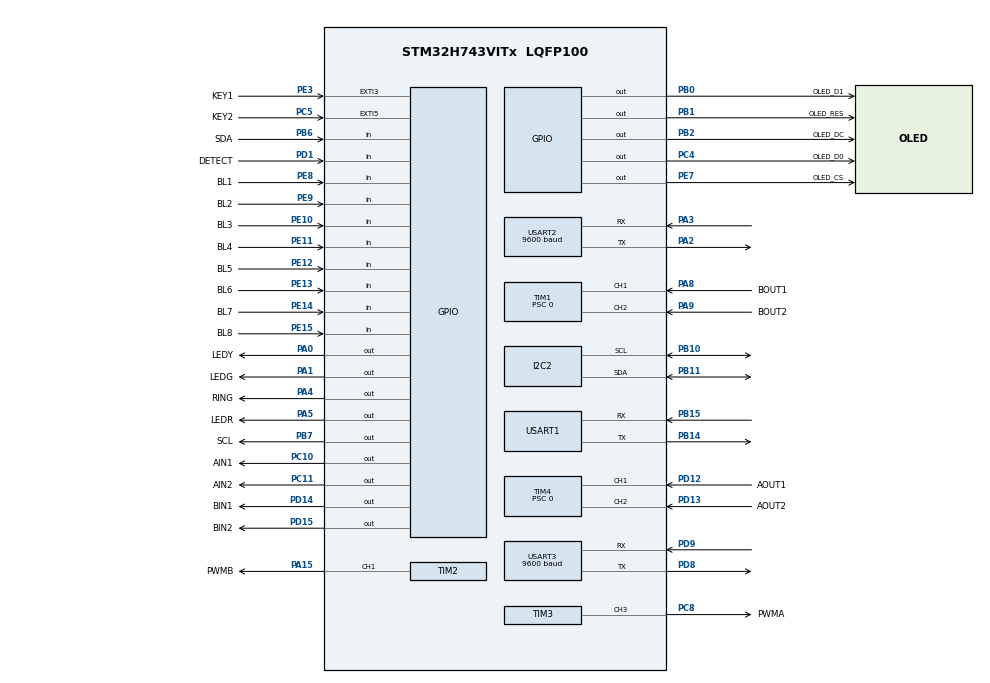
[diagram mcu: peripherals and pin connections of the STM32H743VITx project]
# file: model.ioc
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CORTEX_M7.AccessPermission-Cortex_Memory_Protection_Unit_Region0_Settings=MPU_REGION_FULL_ACCESS
CORTEX_M7.AccessPermission-Cortex_Memory_Protection_Unit_Region1_Settings=MPU_REGION_FULL_ACCESS
CORTEX_M7.AccessPermission-Cortex_Memory_Protection_Unit_Region2_Settings=MPU_REGION_FULL_ACCESS
CORTEX_M7.AccessPermission-Cortex_Memory_Protection_Unit_Region3_Settings=MPU_REGION_FULL_ACCESS
CORTEX_M7.AccessPermission-Cortex_Memory_Protection_Unit_Region4_Settings=MPU_REGION_FULL_ACCESS
CORTEX_M7.BaseAddress-Cortex_Memory_Protection_Unit_Region0_Settings=0x24000000
CORTEX_M7.BaseAddress-Cortex_Memory_Protection_Unit_Region1_Settings=0x30000000
CORTEX_M7.BaseAddress-Cortex_Memory_Protection_Unit_Region2_Settings=0x30020000
CORTEX_M7.BaseAddress-Cortex_Memory_Protection_Unit_Region3_Settings=0x30040000
CORTEX_M7.BaseAddress-Cortex_Memory_Protection_Unit_Region4_Settings=0x38000000
CORTEX_M7.CPU_DCache=Enabled
CORTEX_M7.CPU_ICache=Enabled
CORTEX_M7.Enable-Cortex_Memory_Protection_Unit_Region0_Settings=MPU_REGION_ENABLE
CORTEX_M7.Enable-Cortex_Memory_Protection_Unit_Region1_Settings=MPU_REGION_ENABLE
CORTEX_M7.Enable-Cortex_Memory_Protection_Unit_Region2_Settings=MPU_REGION_ENABLE
CORTEX_M7.Enable-Cortex_Memory_Protection_Unit_Region3_Settings=MPU_REGION_ENABLE
CORTEX_M7.Enable-Cortex_Memory_Protection_Unit_Region4_Settings=MPU_REGION_ENABLE
CORTEX_M7.IsBufferable-Cortex_Memory_Protection_Unit_Region0_Settings=MPU_ACCESS_BUFFERABLE
CORTEX_M7.IsCacheable-Cortex_Memory_Protection_Unit_Region0_Settings=MPU_ACCESS_CACHEABLE
CORTEX_M7.MPU_Control=MPU_PRIVILEGED_DEFAULT
CORTEX_M7.Size-Cortex_Memory_Protection_Unit_Region0_Settings=MPU_REGION_SIZE_512KB
CORTEX_M7.Size-Cortex_Memory_Protection_Unit_Region1_Settings=MPU_REGION_SIZE_128KB
CORTEX_M7.Size-Cortex_Memory_Protection_Unit_Region2_Settings=MPU_REGION_SIZE_128KB
CORTEX_M7.Size-Cortex_Memory_Protection_Unit_Region3_Settings=MPU_REGION_SIZE_32KB
CORTEX_M7.Size-Cortex_Memory_Protection_Unit_Region4_Settings=MPU_REGION_SIZE_64KB
CORTEX_M7.TypeExtField-Cortex_Memory_Protection_Unit_Region0_Settings=MPU_TEX_LEVEL1
CORTEX_M7.TypeExtField-Cortex_Memory_Protection_Unit_Region1_Settings=MPU_TEX_LEVEL1
CORTEX_M7.TypeExtField-Cortex_Memory_Protection_Unit_Region2_Settings=MPU_TEX_LEVEL1
CORTEX_M7.TypeExtField-Cortex_Memory_Protection_Unit_Region3_Settings=MPU_TEX_LEVEL1
CORTEX_M7.TypeExtField-Cortex_Memory_Protection_Unit_Region4_Settings=MPU_TEX_LEVEL1
I2C2.Timing=0x307075B1
Mcu.Family=STM32H7
Mcu.Name=STM32H743VITx
Mcu.Package=LQFP100
NVIC.EXTI3_IRQn=true\:14\:0\:true\:false\:true\:true\:true\:true
NVIC.EXTI9_5_IRQn=true\:15\:0\:true\:false\:true\:true\:true\:true
NVIC.PriorityGroup=NVIC_PRIORITYGROUP_4
NVIC.TIM4_IRQn=true\:3\:0\:true\:false\:true\:true\:true\:true
NVIC.TIM6_DAC_IRQn=true\:1\:0\:true\:false\:true\:true\:true\:true
NVIC.TIM7_IRQn=true\:5\:0\:true\:false\:true\:true\:true\:true
NVIC.USART2_IRQn=true\:0\:0\:false\:false\:true\:true\:true\:true
PA0.GPIO_Label=LEDY
PA0.Signal=GPIO_Output
PA1.GPIO_Label=LEDG
PA1.Signal=GPIO_Output
PA13\ (JTMS/SWDIO).Mode=Serial_Wire
PA13\ (JTMS/SWDIO).Signal=DEBUG_JTMS-SWDIO
PA14\ (JTCK/SWCLK).Mode=Serial_Wire
PA14\ (JTCK/SWCLK).Signal=DEBUG_JTCK-SWCLK
PA15\ (JTDI).GPIO_Label=PWMB 
PA15\ (JTDI).Signal=S_TIM2_CH1_ETR
PA2.Mode=Asynchronous
PA2.Signal=USART2_TX
PA3.Mode=Asynchronous
PA3.Signal=USART2_RX
PA4.GPIO_Label=RING
PA4.Signal=GPIO_Output
PA5.GPIO_Label=LEDR
PA5.Signal=GPIO_Output
PA8.GPIO_Label=BOUT1
PA8.Signal=S_TIM1_CH1
PA9.GPIO_Label=BOUT2
PA9.Signal=S_TIM1_CH2
PB0.GPIO_Label=OLED_D1
PB0.GPIO_PuPd=GPIO_PULLUP
PB0.Signal=GPIO_Output
PB1.GPIO_Label=OLED_RES
PB1.GPIO_PuPd=GPIO_PULLUP
PB1.Signal=GPIO_Output
PB10.Mode=I2C
PB10.Signal=I2C2_SCL
PB11.Mode=I2C
PB11.Signal=I2C2_SDA
PB14.Mode=Asynchronous
PB14.Signal=USART1_TX
PB15.Mode=Asynchronous
PB15.Signal=USART1_RX
PB2.GPIO_Label=OLED_DC
PB2.GPIO_PuPd=GPIO_PULLUP
PB2.Signal=GPIO_Output
PB6.GPIO_Label=SDA
PB6.GPIO_PuPd=GPIO_PULLUP
PB6.Signal=GPIO_Input
PB7.GPIO_Label=SCL
PB7.GPIO_ModeDefaultOutputPP=GPIO_MODE_OUTPUT_PP
PB7.GPIO_PuPd=GPIO_NOPULL
PB7.GPIO_Speed=GPIO_SPEED_FREQ_HIGH
PB7.PinState=GPIO_PIN_RESET
PB7.Signal=GPIO_Output
PC10.GPIO_Label=AIN1
PC10.Signal=GPIO_Output
PC11.GPIO_Label=AIN2
PC11.Signal=GPIO_Output
PC4.GPIO_Label=OLED_D0
PC4.GPIO_PuPd=GPIO_PULLUP
PC4.Signal=GPIO_Output
PC5.GPIO_Label=KEY2
PC5.GPIO_PuPd=GPIO_PULLUP
PC5.Signal=GPXTI5
PC8.GPIO_Label=PWMA
PC8.Signal=S_TIM3_CH3
PD1.GPIO_Label=DETECT
PD1.GPIO_PuPd=GPIO_PULLDOWN
PD1.Signal=GPIO_Input
PD12.GPIO_Label=AOUT1
PD12.Signal=S_TIM4_CH1
PD13.GPIO_Label=AOUT2
PD13.Signal=S_TIM4_CH2
PD14.GPIO_Label=BIN1
PD14.Signal=GPIO_Output
PD15.GPIO_Label=BIN2
PD15.Signal=GPIO_Output
PD8.Mode=Asynchronous
PD8.Signal=USART3_TX
PD9.Mode=Asynchronous
PD9.Signal=USART3_RX
PE10.GPIO_Label=BL3
PE10.GPIO_PuPd=GPIO_PULLUP
PE10.Signal=GPIO_Input
PE11.GPIO_Label=BL4
PE11.GPIO_PuPd=GPIO_PULLUP
PE11.Signal=GPIO_Input
PE12.GPIO_Label=BL5
PE12.GPIO_PuPd=GPIO_PULLUP
PE12.Signal=GPIO_Input
PE13.GPIO_Label=BL6
PE13.GPIO_PuPd=GPIO_PULLUP
PE13.Signal=GPIO_Input
PE14.GPIO_Label=BL7
PE14.GPIO_PuPd=GPIO_PULLUP
PE14.Signal=GPIO_Input
PE15.GPIO_Label=BL8
PE15.GPIO_PuPd=GPIO_PULLUP
PE15.Signal=GPIO_Input
PE3.GPIO_Label=KEY1
PE3.GPIO_PuPd=GPIO_PULLUP
PE3.Signal=GPXTI3
PE7.GPIO_Label=OLED_CS
PE7.GPIO_PuPd=GPIO_PULLUP
PE7.Signal=GPIO_Output
PE8.GPIO_Label=BL1
PE8.GPIO_PuPd=GPIO_PULLUP
PE8.Signal=GPIO_Input
PE9.GPIO_Label=BL2
PE9.GPIO_PuPd=GPIO_PULLUP
PE9.Signal=GPIO_Input
PH0-OSC_IN\ (PH0).Mode=HSE-External-Oscillator
PH0-OSC_IN\ (PH0).Signal=RCC_OSC_IN
PH1-OSC_OUT\ (PH1).Mode=HSE-External-Oscillator
PH1-OSC_OUT\ (PH1).Signal=RCC_OSC_OUT
ProjectManager.HeapSize=0x200
ProjectManager.StackSize=0x7400
ProjectManager.TargetToolchain=MDK-ARM V5.32
RCC.ADCFreq_Value=50390625
RCC.APB1Freq_Value=120000000
RCC.APB2Freq_Value=120000000
RCC.APB3Freq_Value=120000000
RCC.APB4Freq_Value=120000000
RCC.CortexFreq_Value=480000000
RCC.D1PPRE=RCC_APB3_DIV2
RCC.D2PPRE1=RCC_APB1_DIV2
RCC.D2PPRE2=RCC_APB2_DIV2
RCC.D3PPRE=RCC_APB4_DIV2
RCC.DIVM1=5
RCC.DIVN1=192
RCC.HCLKFreq_Value=240000000
RCC.HPRE=RCC_HCLK_DIV2
RCC.HSE_VALUE=25000000
RCC.PLLSourceVirtual=RCC_PLLSOURCE_HSE
RCC.PWR_Regulator_Voltage_Scale=PWR_REGULATOR_VOLTAGE_SCALE0
RCC.ProductRev=revV
RCC.SYSCLKFreq_VALUE=480000000
RCC.SYSCLKSource=RCC_SYSCLKSOURCE_PLLCLK
RCC.USBFreq_Value=480000000
SH.S_TIM1_CH1.0=TIM1_CH1,Encoder_Interface
SH.S_TIM1_CH2.0=TIM1_CH2,Encoder_Interface
SH.S_TIM2_CH1_ETR.0=TIM2_CH1,PWM Generation1 CH1
SH.S_TIM3_CH3.0=TIM3_CH3,PWM Generation3 CH3
SH.S_TIM4_CH1.0=TIM4_CH1,Encoder_Interface
SH.S_TIM4_CH2.0=TIM4_CH2,Encoder_Interface
TIM1.ClockDivision=TIM_CLOCKDIVISION_DIV1
TIM1.EncoderMode=TIM_ENCODERMODE_TI12
TIM1.IC1Filter=12
TIM1.IC1Prescaler=TIM_ICPSC_DIV1
TIM1.IC2Filter=12
TIM1.IC2Prescaler=TIM_ICPSC_DIV1
TIM1.Period=8000
TIM1.Prescaler=0
TIM13.Prescaler=239
TIM2.Channel-PWM\ Generation1\ CH1=TIM_CHANNEL_1
TIM3.Channel-PWM\ Generation3\ CH3=TIM_CHANNEL_3
TIM4.ClockDivision=TIM_CLOCKDIVISION_DIV1
TIM4.EncoderMode=TIM_ENCODERMODE_TI12
TIM4.IC1Filter=12
TIM4.IC1Prescaler=TIM_ICPSC_DIV1
TIM4.IC2Filter=12
TIM4.IC2Prescaler=TIM_ICPSC_DIV1
TIM4.Period=8000
TIM4.Prescaler=0
TIM6.Period=9999
TIM6.Prescaler=239
TIM7.Period=9999
TIM7.Prescaler=239
USART1.VirtualMode-Asynchronous=VM_ASYNC
USART2.BaudRate=9600
USART2.VirtualMode-Asynchronous=VM_ASYNC
USART3.BaudRate=9600
USART3.VirtualMode-Asynchronous=VM_ASYNC
VP_TIM13_VS_ClockSourceINT.Mode=Enable_Timer
VP_TIM17_VS_ClockSourceINT.Mode=Enable_Timer
VP_TIM2_VS_ClockSourceINT.Mode=Internal
VP_TIM3_VS_ClockSourceINT.Mode=Internal
VP_TIM6_VS_ClockSourceINT.Mode=Enable_Timer
VP_TIM7_VS_ClockSourceINT.Mode=Enable_Timer
board=custom

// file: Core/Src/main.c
/* USER CODE BEGIN Header */
/**
  ******************************************************************************
  * @file           : main.c
  * @brief          : Main program body
  ******************************************************************************
  * @attention
  *
  * Copyright (c) 2023 STMicroelectronics.
  * All rights reserved.
  *
  * This software is licensed under terms that can be found in the LICENSE file
  * in the root directory of this software component.
  * If no LICENSE file comes with this software, it is provided AS-IS.
  *
  ******************************************************************************
  */
/* USER CODE END Header */
#include "main.h"

/* USER CODE BEGIN PV */
//volatile bool key1state;
//volatile bool key2state;
volatile int led_beep_flag = 0;
uint8_t g_usart2_receivedata;
/* USER CODE END PV */

void SystemClock_Config(void);
static void MPU_Initialize(void);
static void MPU_Config(void);

int main(void)
{

  /* Enable I-Cache---------------------------------------------------------*/
  SCB_EnableICache();

  /* Enable D-Cache---------------------------------------------------------*/
  SCB_EnableDCache();

  /* MCU Configuration--------------------------------------------------------*/

  /* Reset of all peripherals, Initializes the Flash interface and the Systick. */
  HAL_Init();

  /* MPU Configuration--------------------------------------------------------*/
  MPU_Config();

  /* Configure the system clock */
  SystemClock_Config();

  /* Initialize all configured peripherals */
  MX_GPIO_Init();
  MX_TIM7_Init();
  MX_USART1_UART_Init();
  MX_I2C2_Init();
  MX_TIM1_Init();
  MX_TIM2_Init();
  MX_TIM3_Init();
  MX_TIM4_Init();
  MX_USART2_UART_Init();
  MX_TIM6_Init();
  MX_TIM13_Init();
  MX_TIM17_Init();
  MX_USART3_UART_Init();
  /* USER CODE BEGIN 2 */
  HAL_TIM_Base_Start_IT(&htim7);
  HAL_TIM_Base_Start_IT(&htim6);
	//MPU6050_Init();
	OLED_Init();
	TB6612_Init();
  /* USER CODE END 2 */

  /* Infinite loop */
  /* USER CODE BEGIN WHILE */
  while (1)
  {
    UI_Control();
    /* USER CODE END WHILE */

  }
}

void SystemClock_Config(void)
{
  RCC_OscInitTypeDef RCC_OscInitStruct = {0};
  RCC_ClkInitTypeDef RCC_ClkInitStruct = {0};

  /** Supply configuration update enable
  */
  HAL_PWREx_ConfigSupply(PWR_LDO_SUPPLY);

  /** Configure the main internal regulator output voltage
  */
  __HAL_PWR_VOLTAGESCALING_CONFIG(PWR_REGULATOR_VOLTAGE_SCALE1);

  while(!__HAL_PWR_GET_FLAG(PWR_FLAG_VOSRDY)) {}

  __HAL_RCC_SYSCFG_CLK_ENABLE();
  __HAL_PWR_VOLTAGESCALING_CONFIG(PWR_REGULATOR_VOLTAGE_SCALE0);

  while(!__HAL_PWR_GET_FLAG(PWR_FLAG_VOSRDY)) {}

  /** Initializes the RCC Oscillators according to the specified parameters
  * in the RCC_OscInitTypeDef structure.
  */
  RCC_OscInitStruct.OscillatorType = RCC_OSCILLATORTYPE_HSE;
  RCC_OscInitStruct.HSEState = RCC_HSE_ON;
  RCC_OscInitStruct.PLL.PLLState = RCC_PLL_ON;
  RCC_OscInitStruct.PLL.PLLSource = RCC_PLLSOURCE_HSE;
  RCC_OscInitStruct.PLL.PLLM = 5;
  RCC_OscInitStruct.PLL.PLLN = 192;
  RCC_OscInitStruct.PLL.PLLP = 2;
  RCC_OscInitStruct.PLL.PLLQ = 2;
  RCC_OscInitStruct.PLL.PLLR = 2;
  RCC_OscInitStruct.PLL.PLLRGE = RCC_PLL1VCIRANGE_2;
  RCC_OscInitStruct.PLL.PLLVCOSEL = RCC_PLL1VCOWIDE;
  RCC_OscInitStruct.PLL.PLLFRACN = 0;
  if (HAL_RCC_OscConfig(&RCC_OscInitStruct) != HAL_OK)
  {
    Error_Handler();
  }

  /** Initializes the CPU, AHB and APB buses clocks
  */
  RCC_ClkInitStruct.ClockType = RCC_CLOCKTYPE_HCLK|RCC_CLOCKTYPE_SYSCLK
                              |RCC_CLOCKTYPE_PCLK1|RCC_CLOCKTYPE_PCLK2
                              |RCC_CLOCKTYPE_D3PCLK1|RCC_CLOCKTYPE_D1PCLK1;
  RCC_ClkInitStruct.SYSCLKSource = RCC_SYSCLKSOURCE_PLLCLK;
  RCC_ClkInitStruct.SYSCLKDivider = RCC_SYSCLK_DIV1;
  RCC_ClkInitStruct.AHBCLKDivider = RCC_HCLK_DIV2;
  RCC_ClkInitStruct.APB3CLKDivider = RCC_APB3_DIV2;
  RCC_ClkInitStruct.APB1CLKDivider = RCC_APB1_DIV2;
  RCC_ClkInitStruct.APB2CLKDivider = RCC_APB2_DIV2;
  RCC_ClkInitStruct.APB4CLKDivider = RCC_APB4_DIV2;

  if (HAL_RCC_ClockConfig(&RCC_ClkInitStruct, FLASH_LATENCY_4) != HAL_OK)
  {
    Error_Handler();
  }
}

/* MPU Configuration */

void MPU_Config(void)
{
  MPU_Region_InitTypeDef MPU_InitStruct = {0};

  /* Disables the MPU */
  HAL_MPU_Disable();

  /** Initializes and configures the Region and the memory to be protected
  */
  MPU_InitStruct.Enable = MPU_REGION_ENABLE;
  MPU_InitStruct.Number = MPU_REGION_NUMBER0;
  MPU_InitStruct.BaseAddress = 0x24000000;
  MPU_InitStruct.Size = MPU_REGION_SIZE_512KB;
  MPU_InitStruct.SubRegionDisable = 0x0;
  MPU_InitStruct.TypeExtField = MPU_TEX_LEVEL1;
  MPU_InitStruct.AccessPermission = MPU_REGION_FULL_ACCESS;
  MPU_InitStruct.DisableExec = MPU_INSTRUCTION_ACCESS_ENABLE;
  MPU_InitStruct.IsShareable = MPU_ACCESS_NOT_SHAREABLE;
  MPU_InitStruct.IsCacheable = MPU_ACCESS_CACHEABLE;
  MPU_InitStruct.IsBufferable = MPU_ACCESS_BUFFERABLE;

  HAL_MPU_ConfigRegion(&MPU_InitStruct);

  /** Initializes and configures the Region and the memory to be protected
  */
  MPU_InitStruct.Number = MPU_REGION_NUMBER1;
  MPU_InitStruct.BaseAddress = 0x30000000;
  MPU_InitStruct.Size = MPU_REGION_SIZE_128KB;
  MPU_InitStruct.IsCacheable = MPU_ACCESS_NOT_CACHEABLE;
  MPU_InitStruct.IsBufferable = MPU_ACCESS_NOT_BUFFERABLE;

  HAL_MPU_ConfigRegion(&MPU_InitStruct);

  /** Initializes and configures the Region and the memory to be protected
  */
  MPU_InitStruct.Number = MPU_REGION_NUMBER2;
  MPU_InitStruct.BaseAddress = 0x30020000;

  HAL_MPU_ConfigRegion(&MPU_InitStruct);

  /** Initializes and configures the Region and the memory to be protected
  */
  MPU_InitStruct.Number = MPU_REGION_NUMBER3;
  MPU_InitStruct.BaseAddress = 0x30040000;
  MPU_InitStruct.Size = MPU_REGION_SIZE_32KB;

  HAL_MPU_ConfigRegion(&MPU_InitStruct);

  /** Initializes and configures the Region and the memory to be protected
  */
  MPU_InitStruct.Number = MPU_REGION_NUMBER4;
  MPU_InitStruct.BaseAddress = 0x38000000;
  MPU_InitStruct.Size = MPU_REGION_SIZE_64KB;

  HAL_MPU_ConfigRegion(&MPU_InitStruct);
  /* Enables the MPU */
  HAL_MPU_Enable(MPU_PRIVILEGED_DEFAULT);

}

void Error_Handler(void)
{
  __disable_irq();
  while (1)
  {
  }
}
